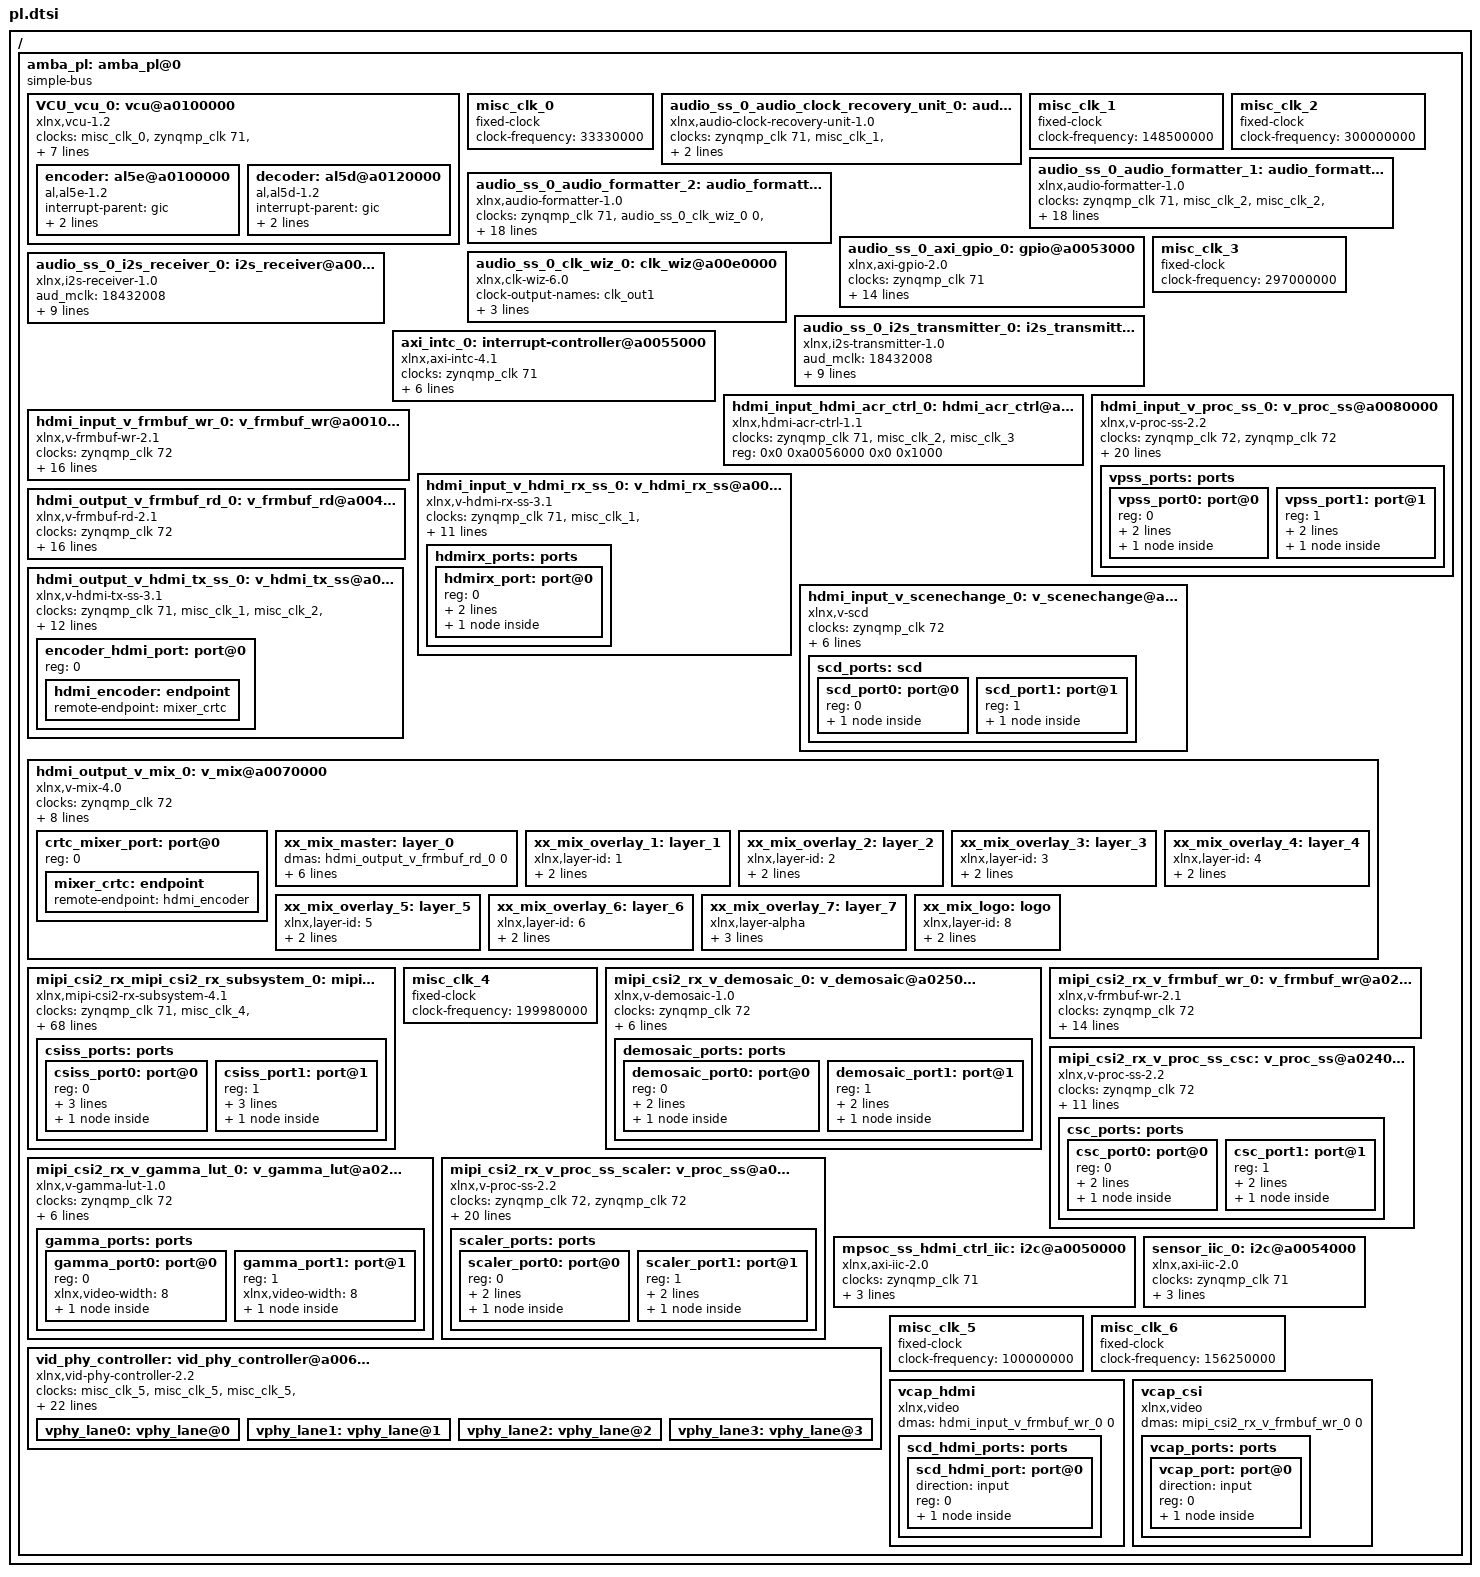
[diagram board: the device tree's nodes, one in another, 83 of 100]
/*
 * CAUTION: This file is automatically generated by Xilinx.
 * Version:  
 * Today is: Mon Apr  6 09:43:13 2020
 */


/ {
	amba_pl: amba_pl@0 {
		#address-cells = <2>;
		#size-cells = <2>;
		compatible = "simple-bus";
		ranges ;
		VCU_vcu_0: vcu@a0100000 {
			#address-cells = <2>;
			#clock-cells = <1>;
			#size-cells = <2>;
			clock-names = "pll_ref", "aclk", "vcu_core_enc", "vcu_core_dec", "vcu_mcu_enc", "vcu_mcu_dec";
			clocks = <&misc_clk_0>, <&zynqmp_clk 71>, <&VCU_vcu_0 1>, <&VCU_vcu_0 2>, <&VCU_vcu_0 3>, <&VCU_vcu_0 4>;
			compatible = "xlnx,vcu-1.2", "xlnx,vcu";
			interrupt-names = "vcu_host_interrupt";
			interrupt-parent = <&gic>;
			interrupts = <0 95 4>;
			ranges ;
			reg = <0x0 0xa0140000 0x0 0x1000>, <0x0 0xa0141000 0x0 0x1000>;
			reg-names = "vcu_slcr", "logicore";
			reset-gpios = <&gpio 119 0>;
			encoder: al5e@a0100000 {
				compatible = "al,al5e-1.2", "al,al5e";
				interrupt-parent = <&gic>;
				interrupts = <0 95 4>;
				reg = <0x0 0xa0100000 0x0 0x10000>;
			};
			decoder: al5d@a0120000 {
				compatible = "al,al5d-1.2", "al,al5d";
				interrupt-parent = <&gic>;
				interrupts = <0 95 4>;
				reg = <0x0 0xa0120000 0x0 0x10000>;
			};
		};
		misc_clk_0: misc_clk_0 {
			#clock-cells = <0>;
			clock-frequency = <33330000>;
			compatible = "fixed-clock";
		};
		audio_ss_0_audio_clock_recovery_unit_0: audio_clock_recovery_unit@a0290000 {
			clock-names = "s_axi_ctrl_aclk", "ref_clk", "acr_clk", "aud_mclk";
			clocks = <&zynqmp_clk 71>, <&misc_clk_1>, <&zynqmp_clk 71>, <&misc_clk_2>;
			compatible = "xlnx,audio-clock-recovery-unit-1.0";
			reg = <0x0 0xa0290000 0x0 0x10000>;
		};
		misc_clk_1: misc_clk_1 {
			#clock-cells = <0>;
			clock-frequency = <148500000>;
			compatible = "fixed-clock";
		};
		misc_clk_2: misc_clk_2 {
			#clock-cells = <0>;
			clock-frequency = <300000000>;
			compatible = "fixed-clock";
		};
		audio_ss_0_audio_formatter_1: audio_formatter@a0052000 {
			clock-names = "s_axi_lite_aclk", "m_axis_mm2s_aclk", "aud_mclk", "s_axis_s2mm_aclk";
			clocks = <&zynqmp_clk 71>, <&misc_clk_2>, <&misc_clk_2>, <&zynqmp_clk 71>;
			compatible = "xlnx,audio-formatter-1.0", "xlnx,audio-formatter-1.0";
			interrupt-names = "irq_mm2s", "irq_s2mm";
			interrupt-parent = <&gic>;
			interrupts = <0 104 4 0 105 4>;
			reg = <0x0 0xa0052000 0x0 0x1000>;
			xlnx,include-mm2s = <0x1>;
			xlnx,include-s2mm = <0x1>;
			xlnx,max-num-channels-mm2s = <0x2>;
			xlnx,max-num-channels-s2mm = <0x2>;
			xlnx,mm2s-addr-width = <0x40>;
			xlnx,mm2s-async-clock = <0x1>;
			xlnx,mm2s-dataformat = <0x3>;
			xlnx,packing-mode-mm2s = <0x0>;
			xlnx,packing-mode-s2mm = <0x0>;
			xlnx,rx = <&hdmi_input_v_hdmi_rx_ss_0>;
			xlnx,s2mm-addr-width = <0x40>;
			xlnx,s2mm-async-clock = <0x1>;
			xlnx,s2mm-dataformat = <0x1>;
			xlnx,tx = <&hdmi_output_v_hdmi_tx_ss_0>;
		};
		audio_ss_0_audio_formatter_2: audio_formatter@a0051000 {
			clock-names = "s_axi_lite_aclk", "m_axis_mm2s_aclk", "aud_mclk", "s_axis_s2mm_aclk";
			clocks = <&zynqmp_clk 71>, <&audio_ss_0_clk_wiz_0 0>, <&audio_ss_0_clk_wiz_0 0>, <&zynqmp_clk 71>;
			compatible = "xlnx,audio-formatter-1.0", "xlnx,audio-formatter-1.0";
			interrupt-names = "irq_mm2s", "irq_s2mm";
			interrupt-parent = <&gic>;
			interrupts = <0 106 4 0 107 4>;
			reg = <0x0 0xa0051000 0x0 0x1000>;
			xlnx,include-mm2s = <0x1>;
			xlnx,include-s2mm = <0x1>;
			xlnx,max-num-channels-mm2s = <0x2>;
			xlnx,max-num-channels-s2mm = <0x2>;
			xlnx,mm2s-addr-width = <0x40>;
			xlnx,mm2s-async-clock = <0x1>;
			xlnx,mm2s-dataformat = <0x3>;
			xlnx,packing-mode-mm2s = <0x0>;
			xlnx,packing-mode-s2mm = <0x0>;
			xlnx,rx = <&audio_ss_0_i2s_receiver_0>;
			xlnx,s2mm-addr-width = <0x40>;
			xlnx,s2mm-async-clock = <0x1>;
			xlnx,s2mm-dataformat = <0x1>;
			xlnx,tx = <&audio_ss_0_i2s_transmitter_0>;
		};
		audio_ss_0_axi_gpio_0: gpio@a0053000 {
			#gpio-cells = <3>;
			clock-names = "s_axi_aclk";
			clocks = <&zynqmp_clk 71>;
			compatible = "xlnx,axi-gpio-2.0", "xlnx,xps-gpio-1.00.a";
			gpio-controller ;
			reg = <0x0 0xa0053000 0x0 0x1000>;
			xlnx,all-inputs = <0x0>;
			xlnx,all-inputs-2 = <0x0>;
			xlnx,all-outputs = <0x1>;
			xlnx,all-outputs-2 = <0x0>;
			xlnx,dout-default = <0x00000000>;
			xlnx,dout-default-2 = <0x00000000>;
			xlnx,gpio-width = <0x20>;
			xlnx,gpio2-width = <0x20>;
			xlnx,interrupt-present = <0x0>;
			xlnx,is-dual = <0x0>;
			xlnx,tri-default = <0xFFFFFFFF>;
			xlnx,tri-default-2 = <0xFFFFFFFF>;
		};
		audio_ss_0_clk_wiz_0: clk_wiz@a00e0000 {
			#clock-cells = <1>;
			clock-names = "s_axi_aclk", "clk_in1";
			clock-output-names = "clk_out1";
			clocks = <&zynqmp_clk 71>, <&zynqmp_clk 74>;
			compatible = "xlnx,clk-wiz-6.0", "xlnx,clocking-wizard";
			reg = <0x0 0xa00e0000 0x0 0x10000>;
			speed-grade = <2>;
		};
		audio_ss_0_i2s_receiver_0: i2s_receiver@a00c0000 {
			aud_mclk = <18432008>;
			clock-names = "s_axi_ctrl_aclk", "aud_mclk", "m_axis_aud_aclk";
			clocks = <&zynqmp_clk 71>, <&audio_ss_0_clk_wiz_0 0>, <&zynqmp_clk 71>;
			compatible = "xlnx,i2s-receiver-1.0", "xlnx,i2s-receiver-1.0";
			interrupt-names = "irq";
			interrupt-parent = <&gic>;
			interrupts = <0 109 4>;
			reg = <0x0 0xa00c0000 0x0 0x10000>;
			xlnx,depth = <0x80>;
			xlnx,dwidth = <0x18>;
			xlnx,num-channels = <0x1>;
			xlnx,snd-pcm = <&audio_ss_0_audio_formatter_2>;
		};
		audio_ss_0_i2s_transmitter_0: i2s_transmitter@a00d0000 {
			aud_mclk = <18432008>;
			clock-names = "s_axi_ctrl_aclk", "aud_mclk", "s_axis_aud_aclk";
			clocks = <&zynqmp_clk 71>, <&audio_ss_0_clk_wiz_0 0>, <&audio_ss_0_clk_wiz_0 0>;
			compatible = "xlnx,i2s-transmitter-1.0", "xlnx,i2s-transmitter-1.0";
			interrupt-names = "irq";
			interrupt-parent = <&gic>;
			interrupts = <0 108 4>;
			reg = <0x0 0xa00d0000 0x0 0x10000>;
			xlnx,depth = <0x80>;
			xlnx,dwidth = <0x18>;
			xlnx,num-channels = <0x1>;
			xlnx,snd-pcm = <&audio_ss_0_audio_formatter_2>;
		};
		axi_intc_0: interrupt-controller@a0055000 {
			#interrupt-cells = <2>;
			clock-names = "s_axi_aclk";
			clocks = <&zynqmp_clk 71>;
			compatible = "xlnx,axi-intc-4.1", "xlnx,xps-intc-1.00.a";
			interrupt-controller ;
			interrupt-names = "irq";
			interrupt-parent = <&gic>;
			interrupts = <0 110 4>;
			reg = <0x0 0xa0055000 0x0 0x1000>;
			xlnx,kind-of-intr = <0x0>;
			xlnx,num-intr-inputs = <0x4>;
		};
		hdmi_input_hdmi_acr_ctrl_0: hdmi_acr_ctrl@a0056000 {
			clock-names = "axi_aclk", "aud_clk", "hdmi_clk";
			clocks = <&zynqmp_clk 71>, <&misc_clk_2>, <&misc_clk_3>;
			compatible = "xlnx,hdmi-acr-ctrl-1.1", "xlnx,hdmi_act_ctrl";
			reg = <0x0 0xa0056000 0x0 0x1000>;
		};
		misc_clk_3: misc_clk_3 {
			#clock-cells = <0>;
			clock-frequency = <297000000>;
			compatible = "fixed-clock";
		};
		hdmi_input_v_frmbuf_wr_0: v_frmbuf_wr@a0010000 {
			#dma-cells = <1>;
			clock-names = "ap_clk";
			clocks = <&zynqmp_clk 72>;
			compatible = "xlnx,v-frmbuf-wr-2.1", "xlnx,axi-frmbuf-wr-v2.1";
			interrupt-names = "interrupt";
			interrupt-parent = <&gic>;
			interrupts = <0 90 4>;
			reg = <0x0 0xa0010000 0x0 0x10000>;
			reset-gpios = <&gpio 78 1>;
			xlnx,dma-addr-width = <64>;
			xlnx,dma-align = <16>;
			xlnx,fid ;
			xlnx,max-height = <2160>;
			xlnx,max-width = <3840>;
			xlnx,pixels-per-clock = <2>;
			xlnx,s-axi-ctrl-addr-width = <0x7>;
			xlnx,s-axi-ctrl-data-width = <0x20>;
			xlnx,vid-formats = "rgb888", "bgr888", "xbgr8888", "xrgb8888", "uyvy", "y8", "vuy888", "xvuy8888", "yuyv", "nv12", "nv16";
			xlnx,video-width = <8>;
		};
		hdmi_input_v_hdmi_rx_ss_0: v_hdmi_rx_ss@a0000000 {
			clock-names = "s_axi_cpu_aclk", "link_clk", "s_axis_audio_aclk", "video_clk", "s_axis_video_aclk";
			clocks = <&zynqmp_clk 71>, <&misc_clk_1>, <&zynqmp_clk 71>, <&misc_clk_3>, <&zynqmp_clk 72>;
			compatible = "xlnx,v-hdmi-rx-ss-3.1", "xlnx,v-hdmi-rx-ss-3.1";
			interrupt-names = "irq";
			interrupt-parent = <&gic>;
			interrupts = <0 91 4>;
			phy-names = "hdmi-phy0", "hdmi-phy1", "hdmi-phy2";
			phys = <&vphy_lane0 0 1 1 0>, <&vphy_lane1 0 1 1 0>, <&vphy_lane2 0 1 1 0>;
			reg = <0x0 0xa0000000 0x0 0x10000>;
			xlnx,audio-enabled ;
			xlnx,edid-ram-size = <0x100>;
			xlnx,input-pixels-per-clock = <2>;
			xlnx,max-bits-per-component = <8>;
			xlnx,snd-pcm = <&audio_ss_0_audio_formatter_1>;
			hdmirx_ports: ports {
				#address-cells = <1>;
				#size-cells = <0>;
				hdmirx_port: port@0 {
					/* Fill the fields xlnx,video-format and xlnx,video-width based on user requirement */
					reg = <0>;
					xlnx,video-format = <0>;
					xlnx,video-width = <10>;
					hdmi_rx_out: endpoint {
						remote-endpoint = <&vpss_scaler_in>;
					};
				};
			};
		};
		hdmi_input_v_proc_ss_0: v_proc_ss@a0080000 {
			clock-names = "aclk_axis", "aclk_ctrl";
			clocks = <&zynqmp_clk 72>, <&zynqmp_clk 72>;
			compatible = "xlnx,v-proc-ss-2.2", "xlnx,v-vpss-scaler-1.0", "xlnx,vpss-scaler";
			reg = <0x0 0xa0080000 0x0 0x40000>;
			reset-gpios = <&gpio 98 1>;
			xlnx,colorspace-support = <0>;
			xlnx,csc-enable-window = "true";
			xlnx,enable-csc = "true";
			xlnx,h-scaler-phases = <64>;
			xlnx,h-scaler-taps = <8>;
			xlnx,max-height = <2160>;
			xlnx,max-num-phases = <64>;
			xlnx,max-width = <3840>;
			xlnx,num-hori-taps = <8>;
			xlnx,num-vert-taps = <8>;
			xlnx,pix-per-clk = <2>;
			xlnx,samples-per-clk = <2>;
			xlnx,scaler-algorithm = <2>;
			xlnx,topology = <0>;
			xlnx,use-uram = <0>;
			xlnx,v-scaler-phases = <64>;
			xlnx,v-scaler-taps = <8>;
			xlnx,video-width = <8>;
			vpss_ports: ports {
				#address-cells = <1>;
				#size-cells = <0>;
				vpss_port0: port@0 {
					/* For xlnx,video-format user needs to fill as per their requirement */
					reg = <0>;
					xlnx,video-format = <3>;
					xlnx,video-width = <8>;
					vpss_scaler_in: endpoint {
						remote-endpoint = <&hdmi_rx_out>;
					};
				};
				vpss_port1: port@1 {
					/* For xlnx,video-format user needs to fill as per their requirement */
					reg = <1>;
					xlnx,video-format = <3>;
					xlnx,video-width = <8>;
					vpss_scaler_out: endpoint {
						remote-endpoint = <&scd_in>;
					};
				};
			};
		};
		hdmi_input_v_scenechange_0: v_scenechange@a0280000 {
			#address-cells = <1>;
			#size-cells = <0>;
			clock-names = "ap_clk";
			clocks = <&zynqmp_clk 72>;
			compatible = "xlnx,v-scd";
			interrupt-names = "interrupt";
			interrupt-parent = <&axi_intc_0>;
			interrupts = <3 2>;
			reg = <0x0 0xa0280000 0x0 0x10000>;
			reset-gpios = <&gpio 88 1>;
			xlnx,max-data-width = <8>;
			xlnx,numstreams = <1>;
			scd_ports: scd {
				#address-cells = <1>;
				#size-cells = <0>;
				scd_port0: port@0 {
					reg = <0>;
					scd_in: endpoint {
						remote-endpoint = <&vpss_scaler_out>;
					};
				};
				scd_port1: port@1 {
					reg = <1>;
					scd_out: endpoint {
						remote-endpoint = <&scd_hdmi_in>;
					};
				};
			};
		};
		hdmi_output_v_frmbuf_rd_0: v_frmbuf_rd@a0040000 {
			#dma-cells = <1>;
			clock-names = "ap_clk";
			clocks = <&zynqmp_clk 72>;
			compatible = "xlnx,v-frmbuf-rd-2.1", "xlnx,axi-frmbuf-rd-v2.1";
			interrupt-names = "interrupt";
			interrupt-parent = <&gic>;
			interrupts = <0 89 4>;
			reg = <0x0 0xa0040000 0x0 0x10000>;
			reset-gpios = <&gpio 79 1>;
			xlnx,dma-addr-width = <64>;
			xlnx,dma-align = <16>;
			xlnx,fid ;
			xlnx,max-height = <2160>;
			xlnx,max-width = <3840>;
			xlnx,pixels-per-clock = <2>;
			xlnx,s-axi-ctrl-addr-width = <0x7>;
			xlnx,s-axi-ctrl-data-width = <0x20>;
			xlnx,vid-formats = "rgb888", "xbgr8888", "xrgb8888", "bgr888", "uyvy", "y8", "vuy888", "xvuy8888", "yuyv", "nv12", "nv16";
			xlnx,video-width = <8>;
		};
		hdmi_output_v_hdmi_tx_ss_0: v_hdmi_tx_ss@a0020000 {
			clock-names = "s_axi_cpu_aclk", "link_clk", "s_axis_audio_aclk", "video_clk", "s_axis_video_aclk";
			clocks = <&zynqmp_clk 71>, <&misc_clk_1>, <&misc_clk_2>, <&misc_clk_3>, <&zynqmp_clk 72>;
			compatible = "xlnx,v-hdmi-tx-ss-3.1", "xlnx,v-hdmi-tx-ss-3.1";
			interrupt-names = "irq";
			interrupt-parent = <&gic>;
			interrupts = <0 93 4>;
			phy-names = "hdmi-phy0", "hdmi-phy1", "hdmi-phy2";
			phys = <&vphy_lane0 0 1 1 1>, <&vphy_lane1 0 1 1 1>, <&vphy_lane2 0 1 1 1>;
			reg = <0x0 0xa0020000 0x0 0x20000>;
			xlnx,audio-enabled ;
			xlnx,input-pixels-per-clock = <2>;
			xlnx,max-bits-per-component = <8>;
			xlnx,snd-pcm = <&audio_ss_0_audio_formatter_1>;
			xlnx,xlnx-hdmi-acr-ctrl = <&hdmi_input_hdmi_acr_ctrl_0>;
			encoder_hdmi_port: port@0 {
				reg = <0>;
				hdmi_encoder: endpoint {
					remote-endpoint = <&mixer_crtc>;
				};
			};
		};
		hdmi_output_v_mix_0: v_mix@a0070000 {
			clock-names = "ap_clk";
			clocks = <&zynqmp_clk 72>;
			compatible = "xlnx,v-mix-4.0", "xlnx,mixer-3.0", "xlnx,mixer-4.0";
			interrupt-names = "interrupt";
			interrupt-parent = <&gic>;
			interrupts = <0 96 4>;
			reg = <0x0 0xa0070000 0x0 0x10000>;
			reset-gpios = <&gpio 94 1>;
			xlnx,bpc = <8>;
			xlnx,dma-addr-width = <32>;
			xlnx,num-layers = <8>;
			xlnx,ppc = <2>;
			crtc_mixer_port: port@0 {
				reg = <0>;
				mixer_crtc: endpoint {
					remote-endpoint = <&hdmi_encoder>;
				};
			};
			xx_mix_master: layer_0 {
				dma-names = "dma0";
				dmas = <&hdmi_output_v_frmbuf_rd_0 0>;
				xlnx,layer-id = <0>;
				xlnx,layer-max-height = <2160>;
				xlnx,layer-max-width = <3840>;
				xlnx,layer-primary ;
				xlnx,layer-streaming ;
				xlnx,vformat = "BG24";
			};
			xx_mix_overlay_1: layer_1 {
				xlnx,layer-id = <1>;
				xlnx,layer-max-width = <1920>;
				xlnx,vformat = "NV12";
			};
			xx_mix_overlay_2: layer_2 {
				xlnx,layer-id = <2>;
				xlnx,layer-max-width = <1920>;
				xlnx,vformat = "NV12";
			};
			xx_mix_overlay_3: layer_3 {
				xlnx,layer-id = <3>;
				xlnx,layer-max-width = <1920>;
				xlnx,vformat = "NV12";
			};
			xx_mix_overlay_4: layer_4 {
				xlnx,layer-id = <4>;
				xlnx,layer-max-width = <1920>;
				xlnx,vformat = "NV12";
			};
			xx_mix_overlay_5: layer_5 {
				xlnx,layer-id = <5>;
				xlnx,layer-max-width = <1920>;
				xlnx,vformat = "NV12";
			};
			xx_mix_overlay_6: layer_6 {
				xlnx,layer-id = <6>;
				xlnx,layer-max-width = <1920>;
				xlnx,vformat = "NV12";
			};
			xx_mix_overlay_7: layer_7 {
				xlnx,layer-alpha ;
				xlnx,layer-id = <7>;
				xlnx,layer-max-width = <1920>;
				xlnx,vformat = "AR24";
			};
			xx_mix_logo: logo {
				xlnx,layer-id = <8>;
				xlnx,logo-height = <64>;
				xlnx,logo-width = <64>;
			};
		};
		mipi_csi2_rx_mipi_csi2_rx_subsystem_0: mipi_csi2_rx_subsystem@a00f0000 {
			clock-names = "lite_aclk", "dphy_clk_200M", "video_aclk";
			clocks = <&zynqmp_clk 71>, <&misc_clk_4>, <&zynqmp_clk 72>;
			compatible = "xlnx,mipi-csi2-rx-subsystem-4.1", "xlnx,mipi-csi2-rx-subsystem-4.0";
			interrupt-names = "csirxss_csi_irq";
			interrupt-parent = <&axi_intc_0>;
			interrupts = <0 2>;
			reg = <0x0 0xa00f0000 0x0 0x10000>;
			xlnx,axis-tdata-width = <32>;
			xlnx,cal-mode = "NONE";
			xlnx,clk-io-swap = "false";
			xlnx,clk-lane-io-position = <0x1a>;
			xlnx,clk-lp-io-swap = "false";
			xlnx,csi-en-activelanes = "true";
			xlnx,csi-en-crc = "true";
			xlnx,csi-filter-userdatatype = "true";
			xlnx,csi-opt1-regs = "false";
			xlnx,csi-pxl-format = "RAW10";
			xlnx,csi2rx-dbg = <0x0>;
			xlnx,data-lane0-io-position = <0x2d>;
			xlnx,data-lane1-io-position = <0x20>;
			xlnx,data-lane2-io-position = <0x11>;
			xlnx,data-lane3-io-position = <0x29>;
			xlnx,dl0-io-swap = "false";
			xlnx,dl0-lp-io-swap = "false";
			xlnx,dl1-io-swap = "false";
			xlnx,dl1-lp-io-swap = "false";
			xlnx,dl2-io-swap = "false";
			xlnx,dl2-lp-io-swap = "false";
			xlnx,dl3-io-swap = "false";
			xlnx,dl3-lp-io-swap = "false";
			xlnx,dphy-lanes = <0x4>;
			xlnx,dphy-mode = "SLAVE";
			xlnx,en-active-lanes ;
			xlnx,en-bg0-pin0 = "false";
			xlnx,en-bg0-pin6 = "false";
			xlnx,en-bg1-pin0 = "true";
			xlnx,en-bg1-pin6 = "false";
			xlnx,en-bg2-pin0 = "false";
			xlnx,en-bg2-pin6 = "false";
			xlnx,en-bg3-pin0 = "true";
			xlnx,en-bg3-pin6 = "false";
			xlnx,en-clk300m = "false";
			xlnx,en-cnts-byte-clk = "false";
			xlnx,en-csi-v2-0 = "false";
			xlnx,en-exdesigns = "false";
			xlnx,en-timeout-regs = "false";
			xlnx,en-vcx = "false";
			xlnx,esc-timeout = <0x6400>;
			xlnx,exdes-board = "ZCU102";
			xlnx,exdes-config = "MIPI_Video_Pipe_Camera_to_Display";
			xlnx,exdes-fmc = "LI-IMX274MIPI-FMC V1.0 Single Sensor";
			xlnx,fifo-rd-en-control = "true";
			xlnx,hs-line-rate = <0x5a0>;
			xlnx,hs-settle-ns = <0x8d>;
			xlnx,hs-timeout = <0x10005>;
			xlnx,idly-group-name = "mipi_csi2rx_idly_group";
			xlnx,idly-tap = <0x1>;
			xlnx,init = <0x186a0>;
			xlnx,is-7series = "false";
			xlnx,is-versal = "false";
			xlnx,max-lanes = <4>;
			xlnx,mipi-slv-int = <0x0>;
			xlnx,ppc = <2>;
			xlnx,rcve-alt-deskew-seq = "false";
			xlnx,rcve-deskew-seq = "false";
			xlnx,share-idlyctrl = "false";
			xlnx,stretch-line-rate = <0x9c4>;
			xlnx,vc = <4>;
			xlnx,vfb ;
			csiss_ports: ports {
				#address-cells = <1>;
				#size-cells = <0>;
				csiss_port0: port@0 {
					/* Fill cfa-pattern=rggb for raw data types, other fields video-format and video-width user needs to fill */
					reg = <0>;
					xlnx,cfa-pattern = "rggb";
					xlnx,video-format = <12>;
					xlnx,video-width = <8>;
					csiss_out: endpoint {
						remote-endpoint = <&demosaic_in>;
					};
				};
				csiss_port1: port@1 {
					/* Fill cfa-pattern=rggb for raw data types, other fields video-format,video-width user needs to fill */
					/* User need to add something like remote-endpoint=<&out> under the node csiss_in:endpoint */
					reg = <1>;
					xlnx,cfa-pattern = "rggb";
					xlnx,video-format = <12>;
					xlnx,video-width = <8>;
					csiss_in: endpoint {
					};
				};
			};
		};
		misc_clk_4: misc_clk_4 {
			#clock-cells = <0>;
			clock-frequency = <199980000>;
			compatible = "fixed-clock";
		};
		mipi_csi2_rx_v_demosaic_0: v_demosaic@a0250000 {
			clock-names = "ap_clk";
			clocks = <&zynqmp_clk 72>;
			compatible = "xlnx,v-demosaic-1.0", "xlnx,v-demosaic";
			reg = <0x0 0xa0250000 0x0 0x10000>;
			reset-gpios = <&gpio 85 1>;
			xlnx,max-height = <2160>;
			xlnx,max-width = <3840>;
			xlnx,s-axi-ctrl-addr-width = <6>;
			xlnx,s-axi-ctrl-data-width = <32>;
			demosaic_ports: ports {
				#address-cells = <1>;
				#size-cells = <0>;
				demosaic_port0: port@0 {
					/* For cfa-pattern=rggb user needs to fill as per BAYER format */
					reg = <0>;
					xlnx,cfa-pattern = "rggb";
					xlnx,video-width = <8>;
					demosaic_in: endpoint {
						remote-endpoint = <&csiss_out>;
					};
				};
				demosaic_port1: port@1 {
					/* For cfa-pattern=rggb user needs to fill as per BAYER format */
					reg = <1>;
					xlnx,cfa-pattern = "rggb";
					xlnx,video-width = <8>;
					demosaic_out: endpoint {
						remote-endpoint = <&gamma_in>;
					};
				};
			};
		};
		mipi_csi2_rx_v_frmbuf_wr_0: v_frmbuf_wr@a0260000 {
			#dma-cells = <1>;
			clock-names = "ap_clk";
			clocks = <&zynqmp_clk 72>;
			compatible = "xlnx,v-frmbuf-wr-2.1", "xlnx,axi-frmbuf-wr-v2.1";
			interrupt-names = "interrupt";
			interrupt-parent = <&axi_intc_0>;
			interrupts = <1 2>;
			reg = <0x0 0xa0260000 0x0 0x10000>;
			reset-gpios = <&gpio 80 1>;
			xlnx,dma-addr-width = <32>;
			xlnx,dma-align = <16>;
			xlnx,max-height = <2160>;
			xlnx,max-width = <3840>;
			xlnx,pixels-per-clock = <2>;
			xlnx,s-axi-ctrl-addr-width = <0x7>;
			xlnx,s-axi-ctrl-data-width = <0x20>;
			xlnx,vid-formats = "bgr888", "xbgr8888", "xrgb8888", "uyvy", "y8", "vuy888", "xvuy8888", "yuyv", "nv12", "nv16";
			xlnx,video-width = <8>;
		};
		mipi_csi2_rx_v_gamma_lut_0: v_gamma_lut@a0270000 {
			clock-names = "ap_clk";
			clocks = <&zynqmp_clk 72>;
			compatible = "xlnx,v-gamma-lut-1.0", "xlnx,v-gamma-lut";
			reg = <0x0 0xa0270000 0x0 0x10000>;
			reset-gpios = <&gpio 86 1>;
			xlnx,max-height = <2160>;
			xlnx,max-width = <3840>;
			xlnx,s-axi-ctrl-addr-width = <13>;
			xlnx,s-axi-ctrl-data-width = <32>;
			gamma_ports: ports {
				#address-cells = <1>;
				#size-cells = <0>;
				gamma_port0: port@0 {
					reg = <0>;
					xlnx,video-width = <8>;
					gamma_in: endpoint {
						remote-endpoint = <&demosaic_out>;
					};
				};
				gamma_port1: port@1 {
					reg = <1>;
					xlnx,video-width = <8>;
					gamma_out: endpoint {
						remote-endpoint = <&csc_in>;
					};
				};
			};
		};
		mipi_csi2_rx_v_proc_ss_csc: v_proc_ss@a0240000 {
			clock-names = "aclk";
			clocks = <&zynqmp_clk 72>;
			compatible = "xlnx,v-proc-ss-2.2", "xlnx,vpss-csc", "xlnx,v-vpss-csc";
			reg = <0x0 0xa0240000 0x0 0x10000>;
			reset-gpios = <&gpio 84 1>;
			xlnx,colorspace-support = <0>;
			xlnx,csc-enable-window = "false";
			xlnx,max-height = <2160>;
			xlnx,max-width = <3840>;
			xlnx,num-video-components = <3>;
			xlnx,samples-per-clk = <2>;
			xlnx,topology = <3>;
			xlnx,use-uram = <0>;
			xlnx,video-width = <8>;
			csc_ports: ports {
				#address-cells = <1>;
				#size-cells = <0>;
				csc_port0: port@0 {
					/* For xlnx,video-format user needs to fill as per their requirement */
					reg = <0>;
					xlnx,video-format = <3>;
					xlnx,video-width = <8>;
					csc_in: endpoint {
						remote-endpoint = <&gamma_out>;
					};
				};
				csc_port1: port@1 {
					/* For xlnx,video-format user needs to fill as per their requirement */
					reg = <1>;
					xlnx,video-format = <3>;
					xlnx,video-width = <8>;
					csc_out: endpoint {
						remote-endpoint = <&scaler_in>;
					};
				};
			};
		};
		mipi_csi2_rx_v_proc_ss_scaler: v_proc_ss@a0200000 {
			clock-names = "aclk_axis", "aclk_ctrl";
			clocks = <&zynqmp_clk 72>, <&zynqmp_clk 72>;
			compatible = "xlnx,v-proc-ss-2.2", "xlnx,v-vpss-scaler-1.0", "xlnx,vpss-scaler";
			reg = <0x0 0xa0200000 0x0 0x40000>;
			reset-gpios = <&gpio 82 1>;
			xlnx,colorspace-support = <0>;
			xlnx,csc-enable-window = "true";
			xlnx,enable-csc = "true";
			xlnx,h-scaler-phases = <64>;
			xlnx,h-scaler-taps = <8>;
			xlnx,max-height = <2160>;
			xlnx,max-num-phases = <64>;
			xlnx,max-width = <3840>;
			xlnx,num-hori-taps = <8>;
			xlnx,num-vert-taps = <8>;
			xlnx,pix-per-clk = <2>;
			xlnx,samples-per-clk = <2>;
			xlnx,scaler-algorithm = <2>;
			xlnx,topology = <0>;
			xlnx,use-uram = <0>;
			xlnx,v-scaler-phases = <64>;
			xlnx,v-scaler-taps = <8>;
			xlnx,video-width = <8>;
			scaler_ports: ports {
				#address-cells = <1>;
				#size-cells = <0>;
				scaler_port0: port@0 {
					/* For xlnx,video-format user needs to fill as per their requirement */
					reg = <0>;
					xlnx,video-format = <3>;
					xlnx,video-width = <8>;
					scaler_in: endpoint {
						remote-endpoint = <&csc_out>;
					};
				};
				scaler_port1: port@1 {
					/* For xlnx,video-format user needs to fill as per their requirement */
					reg = <1>;
					xlnx,video-format = <3>;
					xlnx,video-width = <8>;
					scaler_out: endpoint {
						remote-endpoint = <&vcap_csi_in>;
					};
				};
			};
		};
		mpsoc_ss_hdmi_ctrl_iic: i2c@a0050000 {
			#address-cells = <1>;
			#size-cells = <0>;
			clock-names = "s_axi_aclk";
			clocks = <&zynqmp_clk 71>;
			compatible = "xlnx,axi-iic-2.0", "xlnx,xps-iic-2.00.a";
			interrupt-names = "iic2intc_irpt";
			interrupt-parent = <&gic>;
			interrupts = <0 94 4>;
			reg = <0x0 0xa0050000 0x0 0x1000>;
		};
		sensor_iic_0: i2c@a0054000 {
			#address-cells = <1>;
			#size-cells = <0>;
			clock-names = "s_axi_aclk";
			clocks = <&zynqmp_clk 71>;
			compatible = "xlnx,axi-iic-2.0", "xlnx,xps-iic-2.00.a";
			interrupt-names = "iic2intc_irpt";
			interrupt-parent = <&axi_intc_0>;
			interrupts = <2 2>;
			reg = <0x0 0xa0054000 0x0 0x1000>;
		};
		vid_phy_controller: vid_phy_controller@a0060000 {
			clock-names = "mgtrefclk0_pad_p_in", "mgtrefclk0_pad_n_in", "mgtrefclk1_pad_p_in", "mgtrefclk1_pad_n_in", "gtsouthrefclk1_in", "gtsouthrefclk1_odiv2_in", "vid_phy_tx_axi4s_aclk", "vid_phy_rx_axi4s_aclk", "vid_phy_sb_aclk", "vid_phy_axi4lite_aclk", "drpclk";
			clocks = <&misc_clk_5>, <&misc_clk_5>, <&misc_clk_5>, <&misc_clk_5>, <&misc_clk_6>, <&misc_clk_6>, <&misc_clk_1>, <&misc_clk_1>, <&zynqmp_clk 71>, <&zynqmp_clk 71>, <&zynqmp_clk 71>;
			compatible = "xlnx,vid-phy-controller-2.2", "xlnx,vid-phy-controller-2.1";
			interrupt-names = "irq";
			interrupt-parent = <&gic>;
			interrupts = <0 92 4>;
			reg = <0x0 0xa0060000 0x0 0x10000>;
			xlnx,hdmi-fast-switch = <1>;
			xlnx,input-pixels-per-clock = <2>;
			xlnx,nidru = <1>;
			xlnx,nidru-refclk-sel = <5>;
			xlnx,rx-no-of-channels = <3>;
			xlnx,rx-pll-selection = <0>;
			xlnx,rx-protocol = <1>;
			xlnx,rx-refclk-sel = <1>;
			xlnx,transceiver-type = <5>;
			xlnx,transceiver-width = <2>;
			xlnx,tx-buffer-bypass = <1>;
			xlnx,tx-no-of-channels = <3>;
			xlnx,tx-pll-selection = <6>;
			xlnx,tx-protocol = <1>;
			xlnx,tx-refclk-sel = <0>;
			xlnx,use-gt-ch4-hdmi = <0>;
			vphy_lane0: vphy_lane@0 {
				#phy-cells = <4>;
			};
			vphy_lane1: vphy_lane@1 {
				#phy-cells = <4>;
			};
			vphy_lane2: vphy_lane@2 {
				#phy-cells = <4>;
			};
			vphy_lane3: vphy_lane@3 {
				#phy-cells = <4>;
			};
		};
		misc_clk_5: misc_clk_5 {
			#clock-cells = <0>;
			clock-frequency = <100000000>;
			compatible = "fixed-clock";
		};
		misc_clk_6: misc_clk_6 {
			#clock-cells = <0>;
			clock-frequency = <156250000>;
			compatible = "fixed-clock";
		};
		vcap_hdmi {
			compatible = "xlnx,video";
			dma-names = "port0";
			dmas = <&hdmi_input_v_frmbuf_wr_0 0>;
			scd_hdmi_ports: ports {
				#address-cells = <1>;
				#size-cells = <0>;
				scd_hdmi_port: port@0 {
					direction = "input";
					reg = <0>;
					scd_hdmi_in: endpoint {
						remote-endpoint = <&scd_out>;
					};
				};
			};
		};
		vcap_csi {
			compatible = "xlnx,video";
			dma-names = "port0";
			dmas = <&mipi_csi2_rx_v_frmbuf_wr_0 0>;
			vcap_ports: ports {
				#address-cells = <1>;
				#size-cells = <0>;
				vcap_port: port@0 {
					direction = "input";
					reg = <0>;
					vcap_csi_in: endpoint {
						remote-endpoint = <&scaler_out>;
					};
				};
			};
		};
	};
};
